# rCSL_mcbsp_001 register map
Vendor: Texas Instruments
Peripheral module from a debugger description file (folder OMAPL138_C6748).
Registers are 32-bit, read-write, reset 0x0 unless marked. A register's access mark holds for its fields unless they carry their own. Offsets are as the file gives them; lines under a group give offsets from that group; [hi:lo] are bit positions; {n}, {i} and the like mark numbered series; 'fields as' and 'values as' point back to an identical list; <NAME> marks a mode.

## MCBSP — Multi-Channel Buffered Serial Port
0x00 DRR ro — Data Receive Register
  [31:0] DRR — Data Receive Register(Read Only)
0x04 DXR — Data Transmit Register
  [31:0] DXR — Data Transmit Register(Read/Write)
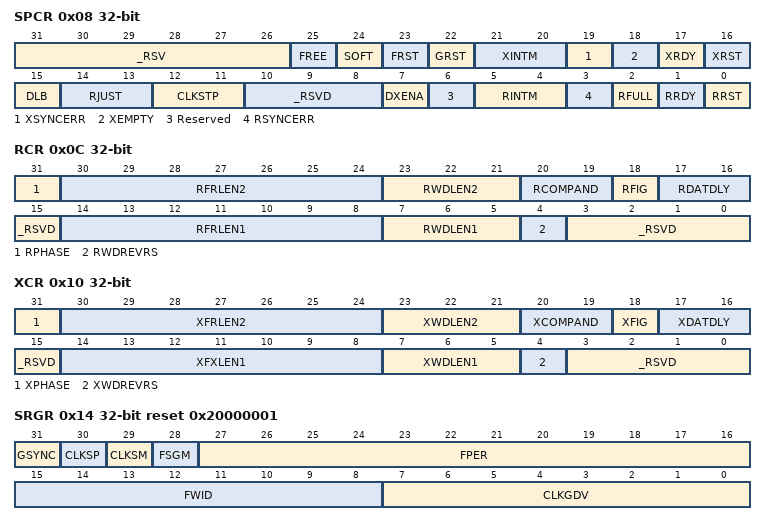
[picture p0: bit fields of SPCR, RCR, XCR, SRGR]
0x08 SPCR access not given — Serial Port Control Register
  [31:26] _RSV ro — These bits are not used
  [25] FREE rw — Controls Free running during emulation mode
    0=DISABLE (Free Running Mode Disabled); 1=ENABLE (Free Running Mode Enabled)
  [24] SOFT rw — Controls the emulation while the FREE bit is set
    0=DISABLE (Soft Running Mode Disabled); 1=ENABLE (Soft Running Mode Enabled)
  [23] FRST rw — Controls the Frame Sync Generator Reset
    0=RESET (Frame Sync Generator is in Reset); 1=FSG (Frame Sync Generator is out of Reset)
  [22] GRST rw — Controls the Sample Rate Generator Reset
    0=RESET (Sample Rate generator is in Reset); 1=CLKG (Sample Rate generator is out of Reset)
  [21:20] XINTM rw — Transmit Interrupt Mode
    0=XRDY (Interrupt driven by XRDY (i.e. end of word) and end of frame in A-bis mode.); 2=FRM (Interrupt driven by a a new frame synchronization); 3=XSYNCERR (Interrupt driven by XSYNCERR)
  [19] XSYNCERR rw — Transmit Synchronization Error
    0=NO (no synchronization error); 1=YES (synchronization error detected by McBSP.)
  [18] XEMPTY ro — Transmit Shift Register (XSR) Empty
    0=YES (XSR is empty); 1=NO (XSR Iis not Empty)
  [17] XRDY ro — Transmitter Ready
    0=NO (Transmitter is not ready); 1=YES (Transmitter is ready with data in DXR)
  [16] XRST rw — Transmitter Resets and enables the Transmitter
    0=DISABLE (Transmitter is disabled and in reset state); 1=ENABLE (Transmitter is enabled)
  [15] DLB rw — Sets Digital Loop Back Mode
    0=DISABLE (Digital loop back mode disabled); 1=ENABLE (Digital loop back mode enabled)
  [14:13] RJUST rw — Enables Receive Sign-Extension and Justification Mode
    0=RZF (right-justify and zero-fill MSBs in DRR); 1=RSE (right-justify and sign-extend MSBs in DRR); 2=LZF (left-justify and zero-fill LSBs in DRR)
  [12:11] CLKSTP rw — Enables Clock Stop Mode for SPI mode.
    0=DISABLE_00 (Clock starts with rising edge without delay); 1=DISABLE_01 (Clock starts with falling edge without delay); 2=NODELAY (Clock stop mode, without clock delay); 3=DELAY (Clock stop mode, with half-cycle clock delay)
  [10:8] _RSVD — These bits are not used (access N)
  [7] DXENA rw — Enables extra delay for turn-on time.
    0=OFF (DX enabler is off); 1=ON (DX enabler is on)
  [6] Reserved — (access N)
  [5:4] RINTM rw — Receive Interrupt Mode
    0=RRDY (Interrupt driven by RRDY (i.e. end of word) and end of frame in A-bis mode.); 2=FRM (Interrupt driven by a a new frame synchronization); 3=RSYNCERR (Interrupt driven by RSYNCERR)
  [3] RSYNCERR rw — Receive Synchronization Error
    values as XSYNCERR
  [2] RFULL ro — Receive Shift Register (RSR) Empty
    0=NO (XSR is empty); 1=YES (XSR Iis not Empty)
  [1] RRDY ro — Receiver Ready
    values as XRDY
  [0] RRST rw — Receiver Reses and enables the Receiver
    values as XRST
0x0C RCR access not given — Receive Control Register
  [31] RPHASE rw — Receive Phase
    0=SINGLE_FRM; 1=DUAL_FRM
  [30:24] RFRLEN2 rw — Receive Frame Length 2
  [23:21] RWDLEN2 rw — Receive Word Length 2
    0=8BIT; 1=12BIT; 2=16BIT; 3=20BIT; 4=24BIT; 5=32BIT
  [20:19] RCOMPAND rw — Receive Companding Mode.
    0=MSB; 1=8BITLSB; 2=ULAW; 3=ALAW
  [18] RFIG rw — Receive Frame Ignore
    0=YES; 1=NO
  [17:16] RDATDLY rw — Receive data delay
    0=0BIT; 1=1BIT; 2=2BIT
  [15] _RSVD — These bits are not used(always cleared) (access N)
  [14:8] RFRLEN1 rw — Receive Frame Length 1
  [7:5] RWDLEN1 rw — Receive Word Length 1
    0=8BIT; 1=12BIT; 2=16BIT; 3=20BIT; 4=24BIT; 5=32BIT
  [4] RWDREVRS rw — Receive 32-bit reversal feature.
    0=DISABLED; 1=ENABLED
  [3:0] _RSVD — These bits are not used(always cleared) (access N)
0x10 XCR access not given — Transmit Control Register
  [31] XPHASE rw — Transmit Phase
    0=SINGLE_FRM; 1=DUAL_FRM
  [30:24] XFRLEN2 rw — Transmit Frame Length 2
  [23:21] XWDLEN2 rw — Transmit Word Length 2
    0=8BIT; 1=12BIT; 2=16BIT; 3=20BIT; 4=24BIT; 5=32BIT
  [20:19] XCOMPAND rw — Transmit Companding Mode.
    0=MSB; 1=8BITLSB; 2=ULAW; 3=ALAW
  [18] XFIG rw — Transmit Frame Ignore
    0=YES; 1=NO
  [17:16] XDATDLY rw — Transmit data delay
    0=0BIT; 1=1BIT; 2=2BIT
  [15] _RSVD — These bits are not used(always cleared) (access N)
  [14:8] XFXLEN1 rw — Transmit Frame Length 1
  [7:5] XWDLEN1 rw — Transmit Word Length 1
    0=8BIT; 1=12BIT; 2=16BIT; 3=20BIT; 4=24BIT; 5=32BIT
  [4] XWDREVRS rw — Transmit 32-bit reversal feature.
    0=DISABLED; 1=ENABLED
  [3:0] _RSVD — These bits are not used(always cleared) (access N)
0x14 SRGR reset 0x20000001 — Sample Rate Generator Register
  [31] GSYNC — Sample rate generator clock synchronization. Only used when the external clock (CLKS) drives the sample rate generator clock (CLKSM=0).
    0=FREE; 1=SYNC
  [30] CLKSP — CLKS Polarity Clock Edge Select. Only used when the external clock CLKS drives the sample rate generator clock (CLKSM=0).
    0=RISING; 1=FALLING
  [29] CLKSM — McBSP Sample Rate Generator Clock Mode
    0=CLKS; 1=INTERNAL
  [28] FSGM — Sample Rate Generator Transmit frame synchronization mode. Used when FSXM=1 in PCR.
    0=DXR2XSR; 1=FSG
  [27:16] FPER — Frame Period. This determines when the next frame sync signal should become active. Range: up to 212 ; 1 to 4096 CLKG periods.
  [15:8] FWID — Frame Width. Determines the width of the frame sync pulse, FSG, during its active period. Range: up to 28 ; 1 to 256 CLKG periods.
  [7:0] CLKGDV — Sample rate generator clock divider. This value is used as the divide-down number to generate the required sample rate generator clock frequency. Default value is 1.
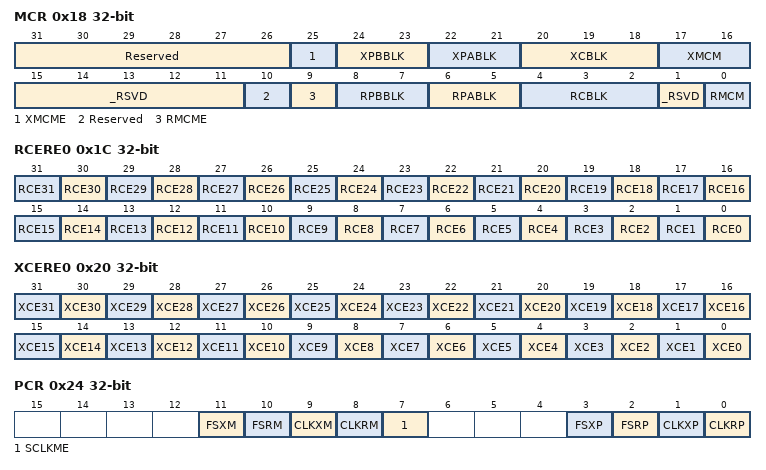
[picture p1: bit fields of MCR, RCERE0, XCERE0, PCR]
0x18 MCR access not given — Multi-Channel Register
  [31:26] Reserved — (access N)
  [25] XMCME rw
    0=2PARTITION; 1=8PARTITION
  [24:23] XPBBLK rw
    0=BLOCK1; 1=BLOCK3; 2=BLOCK5; 3=BLOCK7
  [22:21] XPABLK rw
    0=BLOCK0; 1=BLOCK2; 2=BLOCK4; 3=BLOCK6
  [20:18] XCBLK ro
    {v}=BLOCK{v} (v=0..7)
  [17:16] XMCM rw
    0=ENABLE; 1=DISABLE; 2=ENABLE_MASK; 3=SYMMETRIC
  [15:11] _RSVD — (access N)
  [10] Reserved — (access N)
  [9] RMCME rw
    0=2PARTITION; 1=8PARTITION
  [8:7] RPBBLK rw
    0=BLOCK1; 1=BLOCK3; 2=BLOCK5; 3=BLOCK7
  [6:5] RPABLK rw
    0=BLOCK0; 1=BLOCK2; 2=BLOCK4; 3=BLOCK6
  [4:2] RCBLK ro
    {v}=BLOCK{v} (v=0..7)
  [1] _RSVD — (access N)
  [0] RMCM rw
    0=ENABLE; 1=DISABLE
0x1C RCERE0 — Receive Channel Enable Register Partition A/B (XCER(A/B)) registers are used to enable any of the 32 channels for receive
  [all] fields
    0=DISABLE; 1=ENABLE
  [n] RCE{n} (n=0..31)
0x20 XCERE0 — Transmit Channel Enable Register Partition A/B (XCER(A/B)) registers are used to enable any of the 32 channels for transmit
  [all] fields
    0=DISABLE; 1=ENABLE
  [n] XCE{n} (n=0..31)
0x24 PCR — Pin Control Register
  [11] FSXM — Transmit Frame Synchronization Mode
    0=EXTERNAL (Transmit frame synchronization is supplied by an external source via the FSX pin.); 1=INTERNAL (Transmit frame synchronization is supplied by the McBSP, as determined by the FSGM bit of SRGR2.)
  [10] FSRM — Receive Frame Synchronization Mode
    0=EXTERNAL (Receive frame synchronization is supplied by an external source via the FSR pin.); 1=INTERNAL (Receive frame synchronization is supplied by the sample rate generator FSR is an output pin reflecting internal FSR, except when GSYNC = 1 in SRGR2.)
  [9] CLKXM — Transmitter Clock Mode.
    0=INPUT; 1=OUTPUT
  [8] CLKRM — Receiver Clock Mode
    0=INPUT; 1=OUTPUT
  [7] SCLKME — Enhanced sample clock mode selection bit.
    0=NO; 1=BCLK
  [3] FSXP — Transmit Frame Synchronization Polarity
    0=ACTIVEHIGH; 1=ACTIVELOW
  [2] FSRP — Receive Frame Synchronization Polarity
    0=ACTIVEHIGH; 1=ACTIVELOW
  [1] CLKXP — Transmit Clock Polarity
    0=RISING; 1=FALLING
  [0] CLKRP — Receive Clock Polarity
    0=FALLING; 1=RISING
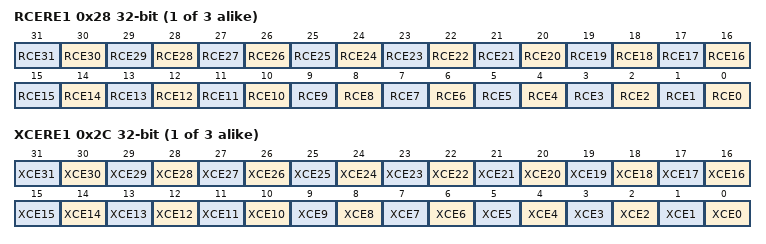
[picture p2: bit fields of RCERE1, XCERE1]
{0x20+8i} RCERE{i} (i=1..3) — Receive Channel Enable Register Partition {i}
  [all] fields
    0=DISABLE; 1=ENABLE
  [n] RCE{n} (n=0..31)
{0x24+8i} XCERE{i} (i=1..3) — Transmit Channel Enable Register Partition {i}
  [all] fields
    0=DISABLE; 1=ENABLE
  [n] XCE{n} (n=0..31)
